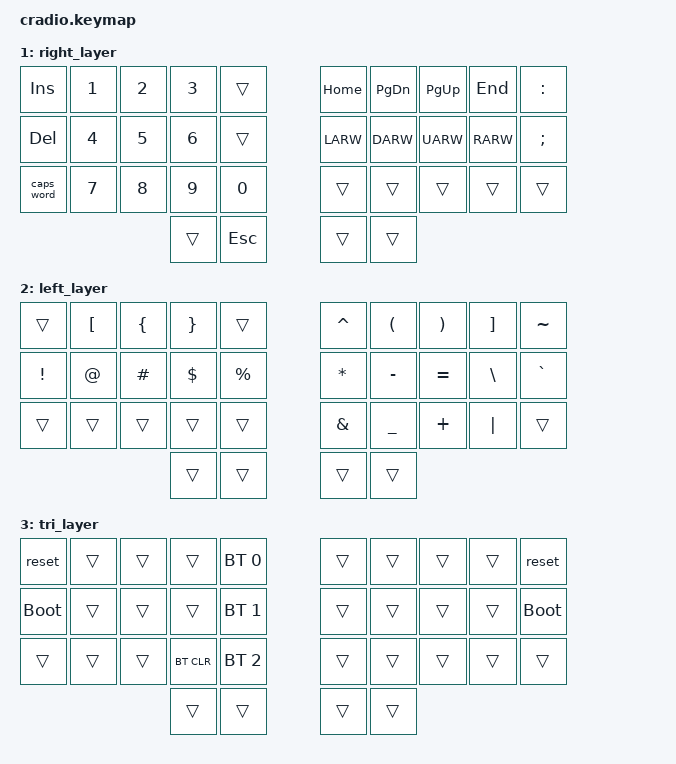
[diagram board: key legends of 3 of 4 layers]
// cradio.keymap
// Copyright (c) 2022 The ZMK Contributors
// SPDX-License-Identifier: MIT

#include <behaviors.dtsi>
#include <dt-bindings/zmk/keys.h>
#include <dt-bindings/zmk/bt.h>

#define AS(keycode) &as LS(keycode) keycode     // Autoshift Macro

/ {
    behaviors {
        as: auto_shift {
            compatible = "zmk,behavior-hold-tap";
            label = "AUTO_SHIFT";
            #binding-cells = <2>;
            tapping_term_ms = <135>;
            quick_tap_ms = <0>;
            flavor = "tap-preferred";
            bindings = <&kp>, <&kp>;
        };
    };
    conditional_layers {
        compatible = "zmk,conditional-layers";
        tri_layer {
            if-layers = <1 2>;
            then-layer = <3>;
        };
    };
    keymap {
        compatible = "zmk,keymap";
        default_layer {
            bindings = <
        //╭──────────┬──────────┬──────────┬──────────┬──────────╮   ╭──────────┬──────────┬──────────┬──────────┬──────────╮
        //│  Q       │  W       │  F       │  P       │  B       │   │  J       │  L       │  U       │  Y       │  ;       │
            AS(Q)      AS(W)      AS(E)      AS(R)      AS(T)          &kp Y      &kp U      &kp I      &kp O      &kp SEMI
        //├──────────┼──────────┼──────────┼──────────┼──────────┤   ├──────────┼──────────┼──────────┼──────────┼──────────┤
        //│  A       │  R       │  S       │  T       │  G       │   │  M       │  N       │  E       │  I       │  O       │
            HRML(A,        S,         D,         F)     &kp G          &kp H      HRMR(J,        K,         L,        SQT)
        //├──────────┼──────────┼──────────┼──────────┼──────────┤   ├──────────┼──────────┼──────────┼──────────┼──────────┤
        //│  Z       │  X       │  C       │  D       │  V       │   │  K       │  H       │ , <      │ . >      │ / ?      │
            &kp Z      &kp X      &kp C      &kp V      &kp B          &kp N      &kp M      &kp COMMA  &kp DOT    &kp FSLH
        //╰──────────┴──────────┴──────────┼──────────┼──────────┤   ├──────────┼──────────┼──────────┴──────────┴──────────╯
        //                                 │  ESC     │  SPC     │   │  BSPC    │  ENT     │
                                                &lt 2 TAB   &kp ENTER     &kp SPACE  &lt 1 BSPC
        //                                 ╰──────────┴──────────╯   ╰──────────┴──────────╯
            >;
        };
        right_layer {
            bindings = <
        //╭──────────┬──────────┬──────────┬──────────┬──────────╮   ╭──────────┬──────────┬──────────┬──────────┬──────────╮
        //│ INSERT   │  1       │  2       │  3       │          │   │ HOME     │ PAGE DN  │ PAGE UP  │ END      │  :       │
            &kp INS    &kp N1     &kp N2     &kp N3     &trans         &kp HOME   &kp PG_DN  &kp PG_UP  &kp END    &kp COLON
        //├──────────┼──────────┼──────────┼──────────┼──────────┤   ├──────────┼──────────┼──────────┼──────────┼──────────┤
        //│ DELETE   │  4       │  5       │  6       │          │   │ LEFT     │ DOWN     │ UP       │ RIGHT    │  ;       │
            &kp DEL    &kp N4     &kp N5     &kp N6     &trans         &kp LARW   &kp DARW   &kp UARW   &kp RARW   &kp SEMI
        //├──────────┼──────────┼──────────┼──────────┼──────────┤   ├──────────┼──────────┼──────────┼──────────┼──────────┤
        //│ CAPS     │  7       │  8       │  9       │  0       │   │          │          │          │          │          │
               &caps_word  &kp N7     &kp N8     &kp N9     &kp N0         &trans     &trans     &trans     &trans     &trans
        //╰──────────┴──────────┴──────────┼──────────┼──────────┤   ├──────────┼──────────┼──────────┴──────────┴──────────╯
                                                     &trans     &kp ESC        &trans     &trans
        //                                 ╰──────────┴──────────╯   ╰──────────┴──────────╯
            >;
        };
        left_layer {
            bindings = <
        //╭──────────┬──────────┬──────────┬──────────┬──────────╮   ╭──────────┬──────────┬──────────┬──────────┬──────────╮
        //│          │  [       │  {       │  }       │          │   │  ^       │  (       │  )       │  ]       │  ~       │
            &trans     &kp LBKT   &kp LBRC   &kp RBRC   &trans         &kp CARET  &kp LPAR   &kp RPAR   &kp RBKT   &kp TILDE
        //├──────────┼──────────┼──────────┼──────────┼──────────┤   ├──────────┼──────────┼──────────┼──────────┼──────────┤
        //│  !       │  @       │  #       │  $       │  %       │   │  *       │  -       │  =       │  \       │  `       │
            &kp EXCL   &kp AT     &kp HASH   &kp DLLR   &kp PRCNT      &kp ASTRK  &kp MINUS  &kp EQUAL  &kp BSLH   &kp GRAVE
        //├──────────┼──────────┼──────────┼──────────┼──────────┤   ├──────────┼──────────┼──────────┼──────────┼──────────┤
        //│          │          │          │          │          │   │  &       │  _       │  +       │  │       │          │
            &trans     &trans     &trans     &trans     &trans         &kp AMPS   &kp UNDER  &kp PLUS   &kp PIPE   &trans
        //╰──────────┴──────────┴──────────┼──────────┼──────────┤   ├──────────┼──────────┼──────────┴──────────┴──────────╯
                                                      &trans     &trans         &trans     &trans
        //                                 ╰──────────┴──────────╯   ╰──────────┴──────────╯
            >;
        };
        tri_layer {
            bindings = <
        //╭──────────┬──────────┬──────────┬──────────┬──────────╮   ╭──────────┬──────────┬──────────┬──────────┬──────────╮
        //│ RESET    │          │          │          │PROFILE 0 │   │          │          │          │          │  RESET   │
            &reset     &trans     &trans     &trans    &bt BT_SEL 0    &trans     &trans     &trans     &trans      &reset
        //├──────────┼──────────┼──────────┼──────────┼──────────┤   ├──────────┼──────────┼──────────┼──────────┼──────────┤
        //│BOOTLOADER│          │          │          │PROFILE 1 │   │          │          │          │          │BOOTLOADER│
           &bootloader  &trans     &trans     &trans    &bt BT_SEL 1    &trans     &trans     &trans     &trans    &bootloader
        //├──────────┼──────────┼──────────┼──────────┼──────────┤   ├──────────┼──────────┼──────────┼──────────┼──────────┤
        //│          │          │          │ CLEAR BT │PROFILE 2 │   │          │          │          │          │          │
            &trans     &trans     &trans    &bt BT_CLR &bt BT_SEL 2    &trans     &trans     &trans     &trans     &trans
        //╰──────────┴──────────┴──────────┼──────────┼──────────┤   ├──────────┼──────────┼──────────┴──────────┴──────────╯
                                                     &trans     &trans         &trans     &trans
        //                                 ╰──────────┴──────────╯   ╰──────────┴──────────╯
            >;
        };
    };
};
